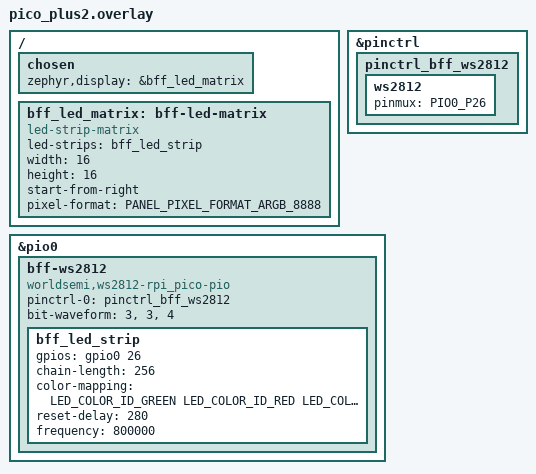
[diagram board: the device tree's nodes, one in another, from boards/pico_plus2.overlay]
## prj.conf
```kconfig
CONFIG_LV_Z_MEM_POOL_SIZE=16384
CONFIG_LV_Z_SHELL=y
CONFIG_MAIN_STACK_SIZE=2048

CONFIG_DISPLAY=y
CONFIG_DISPLAY_LOG_LEVEL_ERR=y

CONFIG_LOG=y
CONFIG_SHELL=y

CONFIG_LVGL=y
CONFIG_LV_MEM_CUSTOM=y
CONFIG_LV_USE_LOG=y
CONFIG_LV_USE_LABEL=y
CONFIG_LV_USE_BTN=y
CONFIG_LV_USE_ARC=y
CONFIG_LV_USE_IMG=y
CONFIG_LV_USE_MONKEY=y
CONFIG_LV_FONT_MONTSERRAT_14=y
CONFIG_LED_STRIP=y
```

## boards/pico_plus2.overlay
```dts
/*
 * Copyright (c) 2024, Ian Wakely
 * SPDX-License-Identifier: Apache-2.0
 */

#include <dt-bindings/pinctrl/rpi-pico-rp2350b-pinctrl.h>
#include <dt-bindings/led/led.h>
#include <zephyr/dt-bindings/display/panel.h>

&pinctrl {
        pinctrl_bff_ws2812: pinctrl_bff_ws2812 {
                ws2812 {
                        pinmux = <PIO0_P26>;
                };
        };
};

&pio0 {
        status = "okay";

        bff-ws2812 {
                compatible = "worldsemi,ws2812-rpi_pico-pio";
                status = "okay";
                pinctrl-0 = <&pinctrl_bff_ws2812>;
                pinctrl-names = "default";
                bit-waveform = <3>, <3>, <4>;

                bff_led_strip: bff_led_strip {
                        status = "okay";
                        gpios = <&gpio0 26 GPIO_ACTIVE_HIGH>;
                        chain-length = <256>;
                        color-mapping = <LED_COLOR_ID_GREEN
                                         LED_COLOR_ID_RED
                                         LED_COLOR_ID_BLUE>;
                        reset-delay = <280>;
                        frequency = <800000>;
                };
        };
};

/ {
        chosen {
                zephyr,display = &bff_led_matrix;
        };

        bff_led_matrix: bff-led-matrix {
                compatible = "led-strip-matrix";
                status = "okay";
                led-strips = <&bff_led_strip>;
                width = <16>;
                height = <16>;
                start-from-right;
		pixel-format = <PANEL_PIXEL_FORMAT_ARGB_8888>;
        };
};
```

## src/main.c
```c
/*
 * Copyright (c) 2018 Jan Van Winkel <jan.van_winkel@dxplore.eu>
 *
 * SPDX-License-Identifier: Apache-2.0
 */

#include <zephyr/device.h>
#include <zephyr/devicetree.h>
#include <zephyr/drivers/display.h>
#include <zephyr/drivers/gpio.h>
#include <lvgl.h>
#include <stdio.h>
#include <string.h>
#include <zephyr/kernel.h>
#include <lvgl_input_device.h>

#define LOG_LEVEL CONFIG_LOG_DEFAULT_LEVEL
#include <zephyr/logging/log.h>
LOG_MODULE_REGISTER(app);

static uint32_t count;


int main(void)
{
	char count_str[11] = {0};
	const struct device *display_dev;
	lv_obj_t *hello_world_label;
	lv_obj_t *count_label;

	display_dev = DEVICE_DT_GET(DT_CHOSEN(zephyr_display));
	if (!device_is_ready(display_dev)) {
		LOG_ERR("Device not ready, aborting test");
		return 0;
	}
static lv_anim_t animation_template;
static lv_style_t label_style;
lv_anim_init(&animation_template);
lv_anim_set_delay(&animation_template, 1000); /*Wait 1 second to start ↪→the first scroll*/
lv_anim_set_repeat_delay(&animation_template, 3000); /*Repeat the scroll 3 seconds after the label␣ Initialize the label style with the animation template*/
lv_style_init(&label_style);
lv_style_set_bg_color(&label_style, lv_color_make(0x00, 0x00, 0x00));
lv_style_set_anim(&label_style, &animation_template);

	//lv_style_t blue_bg_style;
       	//lv_style_init(&blue_bg_style);
lv_obj_add_style(lv_scr_act(), &label_style, 0);
	

	//lv_task_handler();
	display_blanking_off(display_dev);

    lv_obj_t * label2 = lv_label_create(lv_scr_act());
    lv_label_set_long_mode(label2, LV_LABEL_LONG_SCROLL_CIRCULAR);     /*Circular scroll*/
    lv_obj_set_width(label2, 16);
    lv_label_set_text(label2, "Japan Technical Jamboree Episode-2 #4     ");
    lv_obj_align(label2, LV_ALIGN_CENTER, 0, 0);

	while (1) {
		lv_task_handler();
		k_sleep(K_MSEC(100));
	}
}
```
